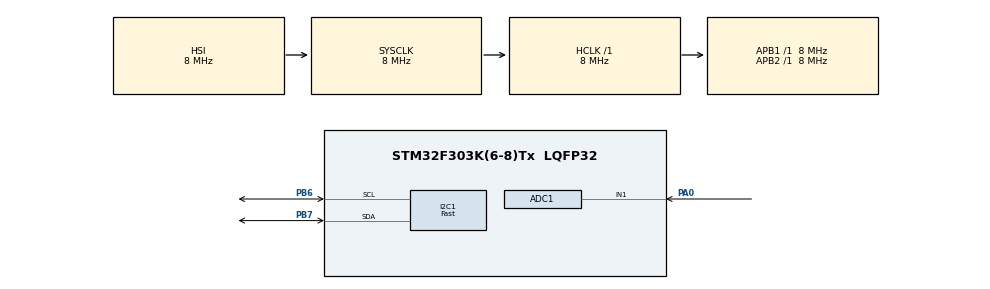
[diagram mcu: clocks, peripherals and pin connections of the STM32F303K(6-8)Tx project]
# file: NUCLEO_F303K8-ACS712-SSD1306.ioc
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ADC1.Channel-8\#ChannelRegularConversion=ADC_CHANNEL_1
ADC1.ContinuousConvMode=ENABLE
ADC1.NbrOfConversionFlag=1
ADC1.Offset-8\#ChannelRegularConversion=0
ADC1.OffsetNumber-8\#ChannelRegularConversion=ADC_OFFSET_NONE
ADC1.Rank-8\#ChannelRegularConversion=1
ADC1.SamplingTime-8\#ChannelRegularConversion=ADC_SAMPLETIME_1CYCLE_5
ADC1.SamplingTimeOPAMP-8\#ChannelRegularConversion=ADC_SAMPLETIME_4CYCLES_5
ADC1.SubFamily=STM32F303x8
ADC1.master=1
I2C1.I2C_Speed_Mode=I2C_Fast
I2C1.Timing=0x0000020B
Mcu.Family=STM32F3
Mcu.Name=STM32F303K(6-8)Tx
Mcu.Package=LQFP32
NVIC.PriorityGroup=NVIC_PRIORITYGROUP_4
PA0.Mode=IN1-Single-Ended
PA0.Signal=ADC1_IN1
PA13.Mode=Serial_Wire
PA13.Signal=SYS_JTMS-SWDIO
PA14.Mode=Serial_Wire
PA14.Signal=SYS_JTCK-SWCLK
PB6.Mode=I2C
PB6.Signal=I2C1_SCL
PB7.Mode=I2C
PB7.Signal=I2C1_SDA
PF0\ /\ OSC_IN.Mode=HSE-External-Oscillator
PF0\ /\ OSC_IN.Signal=RCC_OSC_IN
PF1\ /\ OSC_OUT.Mode=HSE-External-Oscillator
PF1\ /\ OSC_OUT.Signal=RCC_OSC_OUT
ProjectManager.HeapSize=0x200
ProjectManager.StackSize=0x400
ProjectManager.TargetToolchain=STM32CubeIDE
RCC.AHBFreq_Value=8000000
RCC.APB1Freq_Value=8000000
RCC.APB2Freq_Value=8000000
RCC.CortexFreq_Value=8000000
RCC.HSE_VALUE=8000000
RCC.HSI_VALUE=8000000
RCC.SYSCLKFreq_VALUE=8000000
board=NUCLEO-F303K8

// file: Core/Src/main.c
/* USER CODE BEGIN Header */
/**
  ******************************************************************************
  * @file           : main.c
  * @brief          : Main program body
  ******************************************************************************
  * @attention
  *
  * Copyright (c) 2022 STMicroelectronics.
  * All rights reserved.
  *
  * This software is licensed under terms that can be found in the LICENSE file
  * in the root directory of this software component.
  * If no LICENSE file comes with this software, it is provided AS-IS.
  *
  ******************************************************************************
  */
/* USER CODE END Header */
#include "main.h"

/* USER CODE BEGIN Includes */
#include "fonts.h"
#include "ssd1306.h"

/* USER CODE END Includes */

ADC_HandleTypeDef hadc1;

I2C_HandleTypeDef hi2c1;

/* USER CODE BEGIN PV */
uint16_t readValue;
float sensitivity = 0.1; // 0.1 for 20A Model
float rawVoltage;
float current;
/* USER CODE END PV */

void SystemClock_Config(void);
static void MX_GPIO_Init(void);
static void MX_ADC1_Init(void);
static void MX_I2C1_Init(void);

int main(void)
{

  /* MCU Configuration--------------------------------------------------------*/

  /* Reset of all peripherals, Initializes the Flash interface and the Systick. */
  HAL_Init();

  /* Configure the system clock */
  SystemClock_Config();

  /* Initialize all configured peripherals */
  MX_GPIO_Init();
  MX_ADC1_Init();
  MX_I2C1_Init();
  /* USER CODE BEGIN 2 */
  HAL_ADC_Start(&hadc1);

  SSD1306_Init();
  char snum[7];
    SSD1306_GotoXY (15,0);
    SSD1306_Puts ("CURRENT",&Font_11x18, 1);
  /* USER CODE END 2 */

  /* Infinite loop */
  /* USER CODE BEGIN WHILE */
  while (1)
  {
	  HAL_ADC_PollForConversion(&hadc1,1000);
	  readValue = HAL_ADC_GetValue(&hadc1);
	  rawVoltage = (float) readValue * 3.3 * 2 / 4095;

	  current =(rawVoltage - 2.5)/sensitivity;
	  current *=10;
	  if(current < 0){
	  		  current *=-1;
	  	  }
	  HAL_Delay (100);

	  gcvt(current, 6, snum);
	  SSD1306_GotoXY (0, 40);
	  SSD1306_Puts (snum, &Font_11x18, 1);
	  SSD1306_UpdateScreen();
	  SSD1306_GotoXY (100,40);
	  SSD1306_Puts ("mA",&Font_11x18, 1);
    /* USER CODE END WHILE */

  }
}

void SystemClock_Config(void)
{
  RCC_OscInitTypeDef RCC_OscInitStruct = {0};
  RCC_ClkInitTypeDef RCC_ClkInitStruct = {0};
  RCC_PeriphCLKInitTypeDef PeriphClkInit = {0};

  /** Initializes the RCC Oscillators according to the specified parameters
  * in the RCC_OscInitTypeDef structure.
  */
  RCC_OscInitStruct.OscillatorType = RCC_OSCILLATORTYPE_HSI;
  RCC_OscInitStruct.HSIState = RCC_HSI_ON;
  RCC_OscInitStruct.HSICalibrationValue = RCC_HSICALIBRATION_DEFAULT;
  RCC_OscInitStruct.PLL.PLLState = RCC_PLL_ON;
  RCC_OscInitStruct.PLL.PLLSource = RCC_PLLSOURCE_HSI;
  RCC_OscInitStruct.PLL.PLLMUL = RCC_PLL_MUL2;
  if (HAL_RCC_OscConfig(&RCC_OscInitStruct) != HAL_OK)
  {
    Error_Handler();
  }

  /** Initializes the CPU, AHB and APB buses clocks
  */
  RCC_ClkInitStruct.ClockType = RCC_CLOCKTYPE_HCLK|RCC_CLOCKTYPE_SYSCLK
                              |RCC_CLOCKTYPE_PCLK1|RCC_CLOCKTYPE_PCLK2;
  RCC_ClkInitStruct.SYSCLKSource = RCC_SYSCLKSOURCE_HSI;
  RCC_ClkInitStruct.AHBCLKDivider = RCC_SYSCLK_DIV1;
  RCC_ClkInitStruct.APB1CLKDivider = RCC_HCLK_DIV1;
  RCC_ClkInitStruct.APB2CLKDivider = RCC_HCLK_DIV1;

  if (HAL_RCC_ClockConfig(&RCC_ClkInitStruct, FLASH_LATENCY_0) != HAL_OK)
  {
    Error_Handler();
  }
  PeriphClkInit.PeriphClockSelection = RCC_PERIPHCLK_I2C1|RCC_PERIPHCLK_ADC12;
  PeriphClkInit.Adc12ClockSelection = RCC_ADC12PLLCLK_DIV1;
  PeriphClkInit.I2c1ClockSelection = RCC_I2C1CLKSOURCE_HSI;
  if (HAL_RCCEx_PeriphCLKConfig(&PeriphClkInit) != HAL_OK)
  {
    Error_Handler();
  }
}

static void MX_ADC1_Init(void)
{

  ADC_MultiModeTypeDef multimode = {0};
  ADC_ChannelConfTypeDef sConfig = {0};

  /** Common config
  */
  hadc1.Instance = ADC1;
  hadc1.Init.ClockPrescaler = ADC_CLOCK_ASYNC_DIV1;
  hadc1.Init.Resolution = ADC_RESOLUTION_12B;
  hadc1.Init.ScanConvMode = ADC_SCAN_DISABLE;
  hadc1.Init.ContinuousConvMode = ENABLE;
  hadc1.Init.DiscontinuousConvMode = DISABLE;
  hadc1.Init.ExternalTrigConvEdge = ADC_EXTERNALTRIGCONVEDGE_NONE;
  hadc1.Init.ExternalTrigConv = ADC_SOFTWARE_START;
  hadc1.Init.DataAlign = ADC_DATAALIGN_RIGHT;
  hadc1.Init.NbrOfConversion = 1;
  hadc1.Init.DMAContinuousRequests = DISABLE;
  hadc1.Init.EOCSelection = ADC_EOC_SINGLE_CONV;
  hadc1.Init.LowPowerAutoWait = DISABLE;
  hadc1.Init.Overrun = ADC_OVR_DATA_OVERWRITTEN;
  if (HAL_ADC_Init(&hadc1) != HAL_OK)
  {
    Error_Handler();
  }

  /** Configure the ADC multi-mode
  */
  multimode.Mode = ADC_MODE_INDEPENDENT;
  if (HAL_ADCEx_MultiModeConfigChannel(&hadc1, &multimode) != HAL_OK)
  {
    Error_Handler();
  }

  /** Configure Regular Channel
  */
  sConfig.Channel = ADC_CHANNEL_1;
  sConfig.Rank = ADC_REGULAR_RANK_1;
  sConfig.SingleDiff = ADC_SINGLE_ENDED;
  sConfig.SamplingTime = ADC_SAMPLETIME_1CYCLE_5;
  sConfig.OffsetNumber = ADC_OFFSET_NONE;
  sConfig.Offset = 0;
  if (HAL_ADC_ConfigChannel(&hadc1, &sConfig) != HAL_OK)
  {
    Error_Handler();
  }

}

static void MX_I2C1_Init(void)
{

  hi2c1.Instance = I2C1;
  hi2c1.Init.Timing = 0x0000020B;
  hi2c1.Init.OwnAddress1 = 0;
  hi2c1.Init.AddressingMode = I2C_ADDRESSINGMODE_7BIT;
  hi2c1.Init.DualAddressMode = I2C_DUALADDRESS_DISABLE;
  hi2c1.Init.OwnAddress2 = 0;
  hi2c1.Init.OwnAddress2Masks = I2C_OA2_NOMASK;
  hi2c1.Init.GeneralCallMode = I2C_GENERALCALL_DISABLE;
  hi2c1.Init.NoStretchMode = I2C_NOSTRETCH_DISABLE;
  if (HAL_I2C_Init(&hi2c1) != HAL_OK)
  {
    Error_Handler();
  }

  /** Configure Analogue filter
  */
  if (HAL_I2CEx_ConfigAnalogFilter(&hi2c1, I2C_ANALOGFILTER_ENABLE) != HAL_OK)
  {
    Error_Handler();
  }

  /** Configure Digital filter
  */
  if (HAL_I2CEx_ConfigDigitalFilter(&hi2c1, 0) != HAL_OK)
  {
    Error_Handler();
  }

}

static void MX_GPIO_Init(void)
{

  /* GPIO Ports Clock Enable */
  __HAL_RCC_GPIOF_CLK_ENABLE();
  __HAL_RCC_GPIOA_CLK_ENABLE();
  __HAL_RCC_GPIOB_CLK_ENABLE();

}

void Error_Handler(void)
{
  __disable_irq();
  while (1)
  {
  }
}
